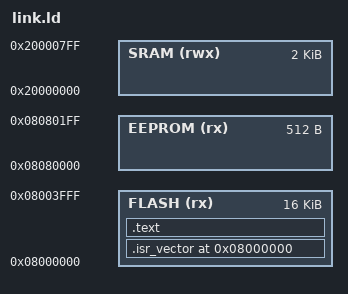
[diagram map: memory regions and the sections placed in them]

/*----------------------------------------------------------------------------
   Linker script automatically generated by AdaCore's startup-gen
   based on template file link.ld.tmplt
----------------------------------------------------------------------------*/

/*----------------------------------------------------------------------------
  Constants
----------------------------------------------------------------------------*/

__FLASH_BASE = 0x8000000;
__FLASH_LEN = 0x4000;

__EEPROM_BASE = 0x8080000;
__EEPROM_LEN = 0x200;

__SRAM_BASE = 0x20000000;
__SRAM_LEN = 0x800;

/*----------------------------------------------------------------------------
  Memories
----------------------------------------------------------------------------*/

/*  Boot memory: FLASH  */
MEMORY
{
   /*  ROM memories  */
   FLASH (rx) : ORIGIN = __FLASH_BASE, LENGTH = __FLASH_LEN
   EEPROM (rx) : ORIGIN = __EEPROM_BASE, LENGTH = __EEPROM_LEN

   /*  RAM memories  */
   SRAM (rwx) : ORIGIN = __SRAM_BASE, LENGTH = __SRAM_LEN
}

/*----------------------------------------------------------------------------
  Sections
----------------------------------------------------------------------------*/

ENTRY(Reset_Handler)

/*
   FLASH
*/
SECTIONS
{
   .isr_vector __FLASH_BASE :
   {
      KEEP(*(.isr_vector))
   } > FLASH

   .text :
   {
      . = ALIGN(4);
      _stext = .;

      *(.text*)
      . = ALIGN(4);
      KEEP(*(.init))
      . = ALIGN(4);
      *(.rodata*)

      . = ALIGN(4);
      _etext = .;
   } > FLASH
   _wtext = (_etext - _stext) >> 2;
}

/*
   SRAM
 */
SECTIONS
{
   .data :
   {
      . = ALIGN(4);
      _sdata = .;

      *(.data*)

      . = ALIGN(4);
      _edata = .;
   } > SRAM AT> FLASH
   _wdata = (_edata - _sdata) >> 2;
   _ldata = LOADADDR(.data);

   .bss (NOLOAD) :
   {
      . = ALIGN(4);
      _sbss = .;

      *(.bss*)

      . = ALIGN(4);
      _ebss = .;
   } > SRAM
   _wbss = (_ebss - _sbss) >> 2;

   .heap (NOLOAD) :
   {
      . = ALIGN(4);
      _sheap = .;

      . = ALIGN(4);
      _eheap = .;
   } > SRAM
   _wheap = (_eheap - _sheap) >> 2;

   .stack (NOLOAD) :
   {
      . = ALIGN(4);
      _sstack = .;

      . = ORIGIN(SRAM) + LENGTH(SRAM);
      _estack = .;
   } > SRAM
   _wstack = (_estack - _sstack) >> 2;
}

/*
   EEPROM
 */
SECTIONS
{
   .eeprom :
   {
      . = ALIGN(4);
      _seeprom = .;

      *(.eeprom*)

      . = ALIGN(4);
      _eeeprom = .;
   } > EEPROM
   _weeprom = (_eeeprom - _seeprom) >> 2;
}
